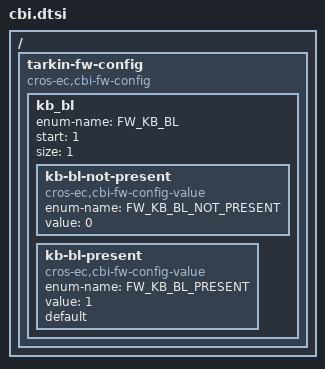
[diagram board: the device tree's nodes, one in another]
/* Copyright 2025 The ChromiumOS Authors
 * Use of this source code is governed by a BSD-style license that can be
 * found in the LICENSE file.
 */

/ {
	tarkin-fw-config {
		compatible = "cros-ec,cbi-fw-config";

		kb_bl {
			enum-name = "FW_KB_BL";
			start = <1>;
			size = <1>;
			kb-bl-not-present {
				compatible = "cros-ec,cbi-fw-config-value";
				enum-name = "FW_KB_BL_NOT_PRESENT";
				value = <0>;
			};
			kb-bl-present {
				compatible = "cros-ec,cbi-fw-config-value";
				enum-name = "FW_KB_BL_PRESENT";
				value = <1>;
                		default;
			};
		};
	};
};
